# R7FA2E2A7 register map
Vendor: Renesas Electronics Corporation; Series: RA2; File version: 1.40.00
CPU: CM23 r1p0, little endian, MPU, no FPU, VTOR, 2 interrupt priority bits, 32 interrupts
Registers are 32-bit, read-write, reset 0x0 unless marked. A register's access mark holds for its fields unless they carry their own. Offsets are from the block's base; [hi:lo] are bit positions; {n}, {i} and the like mark numbered series; <NAME> marks a mode.

## SYSC — System Control
Base 0x4001E000
0x0C SBYCR 16-bit — Standby Control Register
  [15] SSBY — Software Standby Mode Select
    0=Sleep mode; 1=Software Standby mode
0x1C MSTPCRA reset 0xFFBFFFFF — Module Stop Control Register A
  [22] MSTPA22 — DTC Module Stop
    0=Cancel the module-stop state; 1=Enter the module-stop state
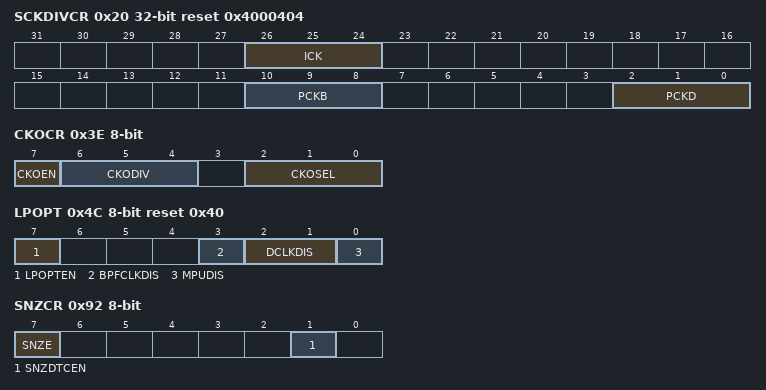
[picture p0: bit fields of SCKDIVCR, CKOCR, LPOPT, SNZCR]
0x20 SCKDIVCR reset 0x4000404 — System Clock Division Control Register
  [all] fields
    0=x 1/1; 1=x 1/2; 2=x 1/4; 3=x 1/8; 4=x 1/16; 5=x 1/32; 6=x 1/64; other=Others (Settings prohibited)
  [26:24] ICK — System Clock (ICLK) Select
  [10:8] PCKB — Peripheral Module Clock B (PCLKB) Select
  [2:0] PCKD — Peripheral Module Clock D (PCLKD) Select
0x26 SCKSCR 8-bit reset 0x1 — System Clock Source Control Register
  [2:0] CKSEL — Clock Source Select
    0=HOCO; 1=MOCO; 2=LOCO; {v}=Setting prohibited (v=3..7)
0x31 MEMWAIT 8-bit — Memory Wait Cycle Control Register for Code Flash
  [0] MEMWAIT — Memory Wait Cycle Select for Code Flash
    0=No wait; 1=Wait
0x36 HOCOCR 8-bit (reset mask 0xFE) — High-Speed On-Chip Oscillator Control Register
  [0] HCSTP — HOCO Stop
    0=Operate the HOCO clock; 1=Stop the HOCO clock
0x38 MOCOCR 8-bit — Middle-Speed On-Chip Oscillator Control Register
  [0] MCSTP — MOCO Stop
    0=MOCO clock is operating; 1=MOCO clock is stopped
0x3C OSCSF 8-bit ro (reset mask 0xFE) — Oscillation Stabilization Flag Register
  [0] HOCOSF — HOCO Clock Oscillation Stabilization Flag
    0=The HOCO clock is stopped or is not yet stable; 1=The HOCO clock is stable, so is available for use as the system clock
0x3E CKOCR 8-bit — Clock Out Control Register
  [7] CKOEN — Clock Out Enable
    0=Disable clock out; 1=Enable clock out
  [6:4] CKODIV — Clock Output Frequency Division Ratio
    0=x 1/1; 1=x 1/2; 2=x 1/4; 3=x 1/8; 4=x 1/16; 5=x 1/32; 6=x 1/64; 7=x 1/128
  [2:0] CKOSEL — Clock Out Source Select
    0=HOCO (value after reset); 1=MOCO; 2=LOCO; 3=Setting prohibited; 4=Setting prohibited; 5=Setting prohibited; other=Others (Setting prohibited)
0x4C LPOPT 8-bit reset 0x40 — Lower Power Operation Control Register
  [7] LPOPTEN — Lower Power Operation Enable
    0=All lower power counter measure disable; 1=All lower power counter measure enable
  [3] BPFCLKDIS — BPF Clock Disable Control
    0=Flash register R/W clock operates as normal; 1=Flash register R/W clock stops
  [2:1] DCLKDIS — Debug Clock Disable Control
    0=Debug clock does not stop; other=Others (Debug clock stops (valid only when LPOPT.LPOPTEN = 1))
  [0] MPUDIS — MPU Clock Disable Control
    0=MPU operates as normal; 1=MPU operate clock stops (MPU function disable)
0x61 MOCOUTCR 8-bit — MOCO User Trimming Control Register
  [7:0] MOCOUTRM — MOCO User Trimming
0x62 HOCOUTCR 8-bit — HOCO User Trimming Control Register
  [7:0] HOCOUTRM — HOCO User Trimming
0x92 SNZCR 8-bit — Snooze Control Register
  [7] SNZE — Snooze mode Enable
    0=Disable Snooze mode; 1=Enable Snooze mode
  [1] SNZDTCEN — DTC Enable in Snooze mode
    0=Disable DTC operation; 1=Enable DTC operation
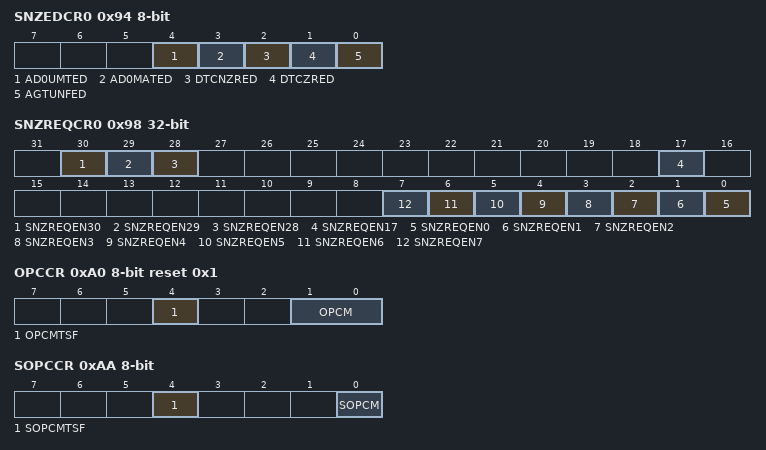
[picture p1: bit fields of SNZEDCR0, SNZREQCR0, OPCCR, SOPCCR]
0x94 SNZEDCR0 8-bit — Snooze End Control Register 0
  [all] fields
    0=Disable the snooze end request; 1=Enable the snooze end request
  [4] AD0UMTED — ADC12 Compare Mismatch Snooze End Enable
  [3] AD0MATED — ADC12 Compare Match Snooze End Enable
  [2] DTCNZRED — Not Last DTC Transmission Completion Snooze End Enable
  [1] DTCZRED — Last DTC Transmission Completion Snooze End Enable
  [0] AGTUNFED — AGT1 Underflow Snooze End Enable
0x98 SNZREQCR0 — Snooze Request Control Register 0
  [all] fields
    0=Disable the snooze request; 1=Enable the snooze request
  [30] SNZREQEN30 — Enable AGT1 compare match B snooze request
  [29] SNZREQEN29 — Enable AGT1 compare match A snooze request
  [28] SNZREQEN28 — Enable AGT1 underflow snooze request
  [17] SNZREQEN17 — Enable KEY_INTKR snooze request
  [n] SNZREQEN{n} (n=0..7) — Enable IRQ{n} pin snooze request
0x9F PSMCR 8-bit — Power Save Memory Control Register
  [1:0] PSMC — Power Save Memory Control
    0=All SRAMs are on in Software Standby mode; 1=4 KB SRAM (0x2000_4000 to 0x2000_4FFF) is on in Software Standby mode; 2=Setting prohibited; 3=Setting prohibited
0xA0 OPCCR 8-bit reset 0x1 — Operating Power Control Register
  [4] OPCMTSF ro — Operating Power Control Mode Transition Status Flag
    0=Transition completed; 1=During transition
  [1:0] OPCM — Operating Power Control Mode Select
    0=High-speed mode; 1=Middle-speed mode; 2=Setting prohibited; 3=Low-speed mode
0xA5 HOCOWTCR 8-bit reset 0x5 — High-Speed On-Chip Oscillator Wait Control Register
  [2:0] HSTS — HOCO Wait Time Setting
    5=Value after reset; 3=Before starting high-speed on-chip oscillator by setting HOCOCR.HCSTP bit, the HSTS[2:0] bits must be set to 011b beforehand. Wait time = 46 cycles (5.75 µs) Wait time is calculated at MOCO = 8 MHz (typically 0.125 µs).; other=Others (Setting prohibited)
0xAA SOPCCR 8-bit — Sub Operating Power Control Register
  [4] SOPCMTSF ro — Operating Power Control Mode Transition Status Flag
    0=Transition completed; 1=During transition
  [0] SOPCM — Sub Operating Power Control Mode Select
    0=Other than Subosc-speed mode; 1=Subosc-speed mode
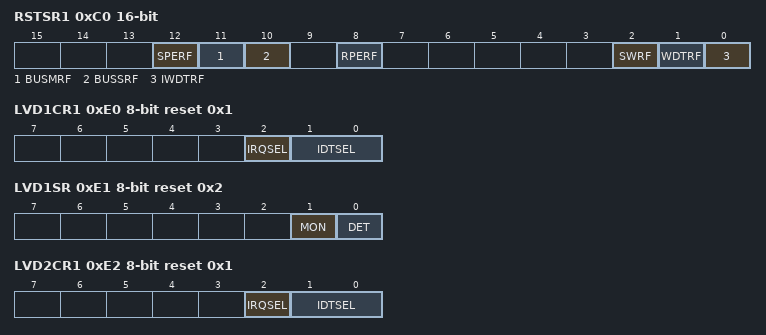
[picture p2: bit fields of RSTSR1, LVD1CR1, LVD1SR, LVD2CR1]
0xC0 RSTSR1 16-bit (reset mask 0xE2F8) — Reset Status Register 1
  [12] SPERF — CPU Stack Pointer Error Reset Detect Flag
    0=CPU stack pointer error reset not detected; 1=CPU stack pointer error reset detected
  [11] BUSMRF — Bus Master MPU Error Reset Detect Flag
    0=Bus master MPU error reset not detected; 1=Bus master MPU error reset detected
  [10] BUSSRF — Bus Slave MPU Error Reset Detect Flag
    0=Bus slave MPU error reset not detected; 1=Bus slave MPU error reset detected
  [8] RPERF — SRAM Parity Error Reset Detect Flag
    0=SRAM parity error reset not detected; 1=SRAM parity error reset detected
  [2] SWRF — Software Reset Detect Flag
    0=Software reset not detected; 1=Software reset detected
  [1] WDTRF — Watchdog Timer Reset Detect Flag
    0=Watchdog timer reset not detected; 1=Watchdog timer reset detected
  [0] IWDTRF — Independent Watchdog Timer Reset Detect Flag
    0=Independent watchdog timer reset not detected; 1=Independent watchdog timer reset detected
0xE0 LVD1CR1 8-bit reset 0x1 — Voltage Monitor 1 Circuit Control Register
  [2] IRQSEL — Voltage Monitor 1 Interrupt Type Select
    0=Non-maskable interrupt; 1=Maskable interrupt
  [1:0] IDTSEL — Voltage Monitor 1 Interrupt Generation Condition Select
    0=When VCC >= Vdet1 (rise) is detected; 1=When VCC < Vdet1 (fall) is detected; 2=When fall and rise are detected; 3=Settings prohibited
0xE1 LVD1SR 8-bit reset 0x2 — Voltage Monitor 1 Circuit Status Register
  [1] MON ro — Voltage Monitor 1 Signal Monitor Flag
    0=VCC < Vdet1; 1=VCC >= Vdet1 or MON is disabled
  [0] DET — Voltage Monitor 1 Voltage Variation Detection Flag
    0=Not detected; 1=Vdet1 crossing is detected
0xE2 LVD2CR1 8-bit reset 0x1 — Voltage Monitor 2 Circuit Control Register 1
  [2] IRQSEL — Voltage Monitor 2 Interrupt Type Select
    0=Non-maskable interrupt; 1=Maskable interrupt
  [1:0] IDTSEL — Voltage Monitor 2 Interrupt Generation Condition Select
    0=When VCC>= Vdet2 (rise) is detected; 1=When VCC < Vdet2 (fall) is detected; 2=When fall and rise are detected; 3=Settings prohibited
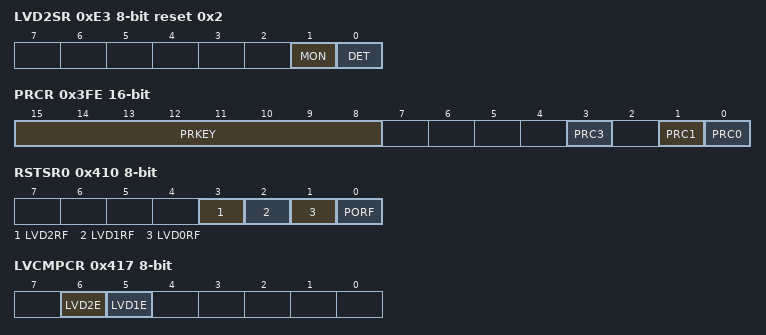
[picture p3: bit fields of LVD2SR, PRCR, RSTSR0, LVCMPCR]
0xE3 LVD2SR 8-bit reset 0x2 — Voltage Monitor 2 Circuit Status Register
  [1] MON ro — Voltage Monitor 2 Signal Monitor Flag
    0=VCC < Vdet2; 1=VCC>= Vdet2 or MON is disabled
  [0] DET — Voltage Monitor 2 Voltage Variation Detection Flag
    0=Not detected; 1=Vdet2 crossing is detected
0x3FE PRCR 16-bit — Protect Register
  [15:8] PRKEY wo — PRC Key Code
  [3] PRC3 — Enable writing to the registers related to the LVD
    0=Disable writes; 1=Enable writes
  [1] PRC1 — Enable writing to the registers related to the low power modes
    0=Disable writes; 1=Enable writes
  [0] PRC0 — Enable writing to the registers related to the clock generation circuit
    0=Disable writes; 1=Enable writes
0x40E SYOCDCR 8-bit — System Control OCD Control Register
  [7] DBGEN — Debugger Enable bit
    0=On-chip debugger is disabled; 1=On-chip debugger is enabled
0x410 RSTSR0 8-bit (reset mask 0xF0) — Reset Status Register 0
  [3] LVD2RF — Voltage Monitor 2 Reset Detect Flag
    0=Voltage monitor 2 reset not detected; 1=Voltage monitor 2 reset detected
  [2] LVD1RF — Voltage Monitor 1 Reset Detect Flag
    0=Voltage monitor 1 reset not detected; 1=Voltage monitor 1 reset detected
  [1] LVD0RF — Voltage Monitor 0 Reset Detect Flag
    0=Voltage monitor 0 reset not detected; 1=Voltage monitor 0 reset detected
  [0] PORF — Power-On Reset Detect Flag
    0=Power-on reset not detected; 1=Power-on reset detected
0x411 RSTSR2 8-bit (reset mask 0xFE) — Reset Status Register 2
  [0] CWSF — Cold/Warm Start Determination Flag
    0=Cold start; 1=Warm start
0x417 LVCMPCR 8-bit — Voltage Monitor Circuit Control Register
  [6] LVD2E — Voltage Detection 2 Enable
    0=Voltage detection 2 circuit disabled; 1=Voltage detection 2 circuit enabled
  [5] LVD1E — Voltage Detection 1 Enable
    0=Voltage detection 1 circuit disabled; 1=Voltage detection 1 circuit enabled
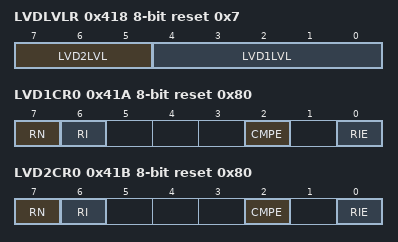
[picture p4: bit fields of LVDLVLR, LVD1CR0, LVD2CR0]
0x418 LVDLVLR 8-bit reset 0x7 — Voltage Detection Level Select Register
  [7:5] LVD2LVL — Voltage Detection 2 Level Select (Standard voltage during fall in voltage)
    {v}=Vdet2_{v} (v=0..3); other=Others (Setting prohibited)
  [4:0] LVD1LVL — Voltage Detection 1 Level Select (Standard voltage during fall in voltage)
    {v}=Vdet1_{v} (v=0..9); 10=Vdet1_A; 11=Vdet1_B; 12=Vdet1_C; 13=Vdet1_D; 14=Vdet1_E; 15=Vdet1_F; other=Others (Setting prohibited)
0x41A LVD1CR0 8-bit reset 0x80 — Voltage Monitor 1 Circuit Control Register 0
  [7] RN — Voltage Monitor 1 Reset Negate Select
    0=Negate after a stabilization time (tLVD1) when VCC > Vdet1 is detected; 1=Negate after a stabilization time (tLVD1) on assertion of the LVD1 reset
  [6] RI — Voltage Monitor 1 Circuit Mode Select
    0=Generate voltage monitor 1 interrupt on Vdet1 crossing; 1=Enable voltage monitor 1 reset when the voltage falls to and below Vdet1
  [2] CMPE — Voltage Monitor 1 Circuit Comparison Result Output Enable
    0=Disable voltage monitor 1 circuit comparison result output; 1=Enable voltage monitor 1 circuit comparison result output
  [0] RIE — Voltage Monitor 1 Interrupt/Reset Enable
    0=Disable; 1=Enable
0x41B LVD2CR0 8-bit reset 0x80 — Voltage Monitor 2 Circuit Control Register 0
  [7] RN — Voltage Monitor 2 Reset Negate Select
    0=Negate after a stabilization time (tLVD2) when VCC > Vdet2 is detected; 1=Negate after a stabilization time (tLVD2) on assertion of the LVD2 reset
  [6] RI — Voltage Monitor 2 Circuit Mode Select
    0=Generate voltage monitor 2 interrupt on Vdet2 crossing; 1=Enable voltage monitor 2 reset when the voltage falls to and below Vdet2
  [2] CMPE — Voltage Monitor 2 Circuit Comparison Result Output Enable
    0=Disable voltage monitor 2 circuit comparison result output; 1=Enable voltage monitor 2 circuit comparison result output
  [0] RIE — Voltage Monitor 2 Interrupt/Reset Enable
    0=Disable; 1=Enable
0x490 LOCOCR 8-bit — Low-Speed On-Chip Oscillator Control Register
  [0] LCSTP — LOCO Stop
    0=Operate the LOCO clock; 1=Stop the LOCO clock
0x492 LOCOUTCR 8-bit — LOCO User Trimming Control Register
  [7:0] LOCOUTRM — LOCO User Trimming
